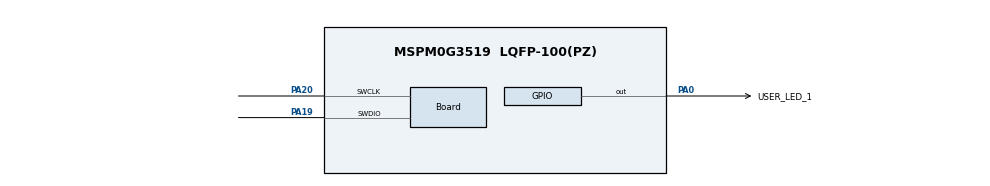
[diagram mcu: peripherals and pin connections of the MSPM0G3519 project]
//@cliArgs --device "MSPM0G351X" --package "LQFP-100(PZ)" --part "Default"
//@v2CliArgs --device "MSPM0G3519" --package "LQFP-100(PZ)"
// @cliArgs --board /ti/boards/LP_MSPM0G3519 --rtos nortos

/**
 * Import the modules used in this configuration.
 */
const ADC12  = scripting.addModule("/ti/driverlib/ADC12", {}, false);
const ADC121 = ADC12.addInstance();
const GPIO   = scripting.addModule("/ti/driverlib/GPIO", {}, false);
const GPIO1  = GPIO.addInstance();
const SYSCTL = scripting.addModule("/ti/driverlib/SYSCTL");
const TIMER  = scripting.addModule("/ti/driverlib/TIMER", {}, false);
const TIMER1 = TIMER.addInstance();

/**
 * Write custom configuration values to the imported modules.
 */
ADC121.$name                       = "ADC12_0";
ADC121.sampClkDiv                  = "DL_ADC12_CLOCK_DIVIDE_8";
ADC121.repeatMode                  = true;
ADC121.trigSrc                     = "DL_ADC12_TRIG_SRC_EVENT";
ADC121.adcMem0wincomp              = true;
ADC121.sampleTime0                 = "25 us";
ADC121.enabledInterrupts           = ["DL_ADC12_INTERRUPT_WINDOW_COMP_HIGH","DL_ADC12_INTERRUPT_WINDOW_COMP_LOW"];
ADC121.subChanID                   = 1;
ADC121.adcMem0chansel              = "DL_ADC12_INPUT_CHAN_12";
ADC121.peripheral.$assign          = "ADC0";
ADC121.peripheral.adcPin12.$assign = "PA14";
ADC121.adcPin12Config.$name        = "ti_driverlib_gpio_GPIOPinGeneric0";

const Board                       = scripting.addModule("/ti/driverlib/Board", {}, false);
Board.configureUnused             = true;
Board.peripheral.$assign          = "DEBUGSS";
Board.peripheral.swclkPin.$assign = "PA20";
Board.peripheral.swdioPin.$assign = "PA19";

GPIO1.$name                          = "GPIO_LEDS";
GPIO1.associatedPins[0].$name        = "USER_LED_1";
GPIO1.associatedPins[0].initialValue = "SET";
GPIO1.associatedPins[0].pin.$assign  = "PA0";

SYSCTL.powerPolicy           = "STOP2";
SYSCTL.forceDefaultClkConfig = true;
SYSCTL.clockTreeEn           = true;

TIMER1.$name                       = "TIMER_0";
TIMER1.timerClkSrc                 = "LFCLK";
TIMER1.timerPeriod                 = "1000 ms";
TIMER1.timerClkPrescale            = 8;
TIMER1.timerMode                   = "PERIODIC";
TIMER1.event1PublisherChannel      = 1;
TIMER1.event1ControllerInterruptEn = ["ZERO_EVENT"];
TIMER1.peripheral.$assign          = "TIMG0";

const ProjectConfig              = scripting.addModule("/ti/project_config/ProjectConfig", {}, false);
ProjectConfig.migrationCondition = true;
